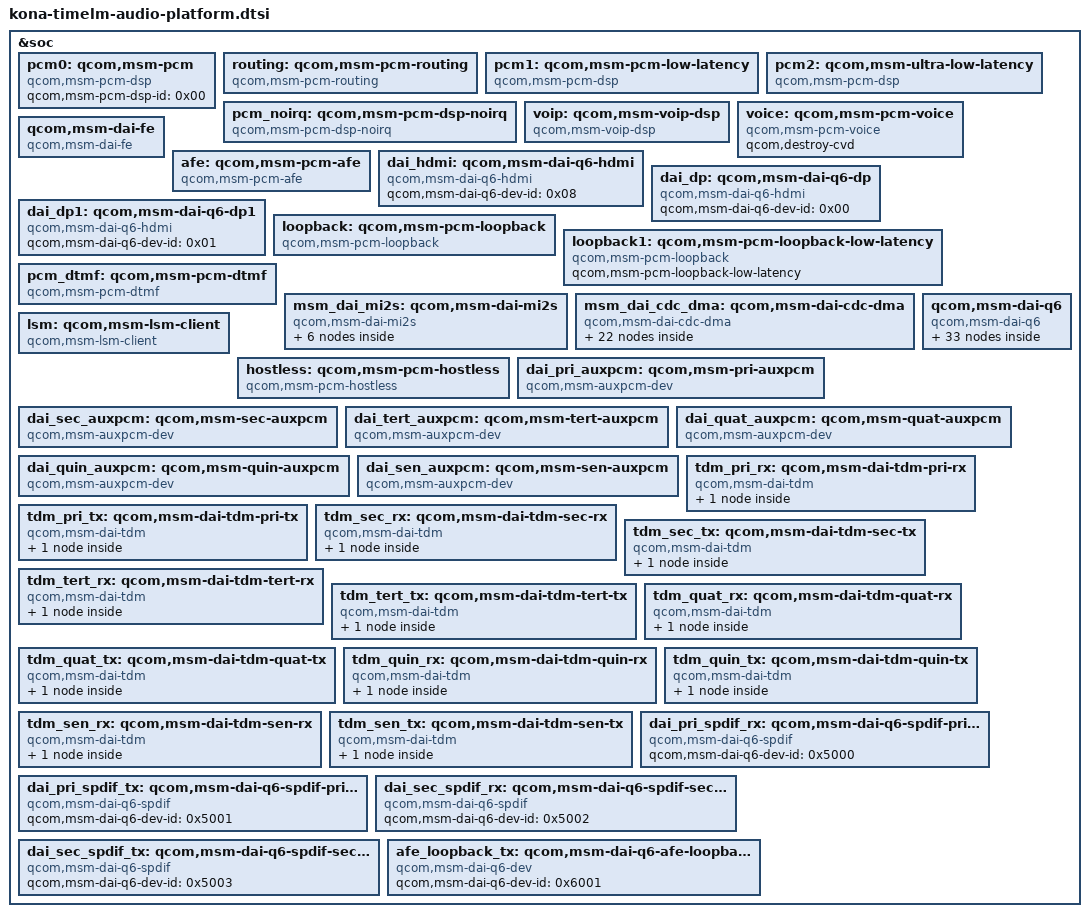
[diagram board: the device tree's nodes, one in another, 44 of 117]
/* Generated by timelm-bsp/tools/extract-live-nodes.py from v60-live.dts */
&soc {
	pcm0: qcom,msm-pcm {
		compatible = "qcom,msm-pcm-dsp";
		qcom,msm-pcm-dsp-id = <0x00>;
	};

	routing: qcom,msm-pcm-routing {
		compatible = "qcom,msm-pcm-routing";
	};

	pcm1: qcom,msm-pcm-low-latency {
		compatible = "qcom,msm-pcm-dsp";
		qcom,msm-pcm-dsp-id = <0x01>;
		qcom,msm-pcm-low-latency;
		qcom,latency-level = "regular";
	};

	pcm2: qcom,msm-ultra-low-latency {
		compatible = "qcom,msm-pcm-dsp";
		qcom,msm-pcm-dsp-id = <0x02>;
		qcom,msm-pcm-low-latency;
		qcom,latency-level = "ultra";
	};

	pcm_noirq: qcom,msm-pcm-dsp-noirq {
		compatible = "qcom,msm-pcm-dsp-noirq";
		qcom,msm-pcm-low-latency;
		qcom,latency-level = "ultra";
	};

	voip: qcom,msm-voip-dsp {
		compatible = "qcom,msm-voip-dsp";
	};

	voice: qcom,msm-pcm-voice {
		compatible = "qcom,msm-pcm-voice";
		qcom,destroy-cvd;
	};

	qcom,msm-dai-fe {
		compatible = "qcom,msm-dai-fe";
	};

	afe: qcom,msm-pcm-afe {
		compatible = "qcom,msm-pcm-afe";
	};

	dai_hdmi: qcom,msm-dai-q6-hdmi {
		compatible = "qcom,msm-dai-q6-hdmi";
		qcom,msm-dai-q6-dev-id = <0x08>;
	};

	dai_dp: qcom,msm-dai-q6-dp {
		compatible = "qcom,msm-dai-q6-hdmi";
		qcom,msm-dai-q6-dev-id = <0x00>;
	};

	dai_dp1: qcom,msm-dai-q6-dp1 {
		compatible = "qcom,msm-dai-q6-hdmi";
		qcom,msm-dai-q6-dev-id = <0x01>;
	};

	loopback: qcom,msm-pcm-loopback {
		compatible = "qcom,msm-pcm-loopback";
	};

	loopback1: qcom,msm-pcm-loopback-low-latency {
		compatible = "qcom,msm-pcm-loopback";
		qcom,msm-pcm-loopback-low-latency;
	};

	pcm_dtmf: qcom,msm-pcm-dtmf {
		compatible = "qcom,msm-pcm-dtmf";
	};

	msm_dai_mi2s: qcom,msm-dai-mi2s {
		compatible = "qcom,msm-dai-mi2s";

		dai_mi2s0: qcom,msm-dai-q6-mi2s-prim {
			compatible = "qcom,msm-dai-q6-mi2s";
			qcom,msm-dai-q6-mi2s-dev-id = <0x00>;
			qcom,msm-mi2s-rx-lines = <0x02>;
			qcom,msm-mi2s-tx-lines = <0x01>;
			pinctrl-names = "default", "sleep";
			pinctrl-0 = <&pri_mi2s_sck_active &pri_mi2s_ws_active &pri_mi2s_sd0_active &pri_mi2s_sd1_active>;
			pinctrl-1 = <&pri_mi2s_sck_sleep &pri_mi2s_ws_sleep &pri_mi2s_sd0_sleep &pri_mi2s_sd1_sleep>;
		};

		dai_mi2s1: qcom,msm-dai-q6-mi2s-sec {
			compatible = "qcom,msm-dai-q6-mi2s";
			qcom,msm-dai-q6-mi2s-dev-id = <0x01>;
			qcom,msm-mi2s-rx-lines = <0x02>;
			qcom,msm-mi2s-tx-lines = <0x01>;
		};

		dai_mi2s2: qcom,msm-dai-q6-mi2s-tert {
			compatible = "qcom,msm-dai-q6-mi2s";
			qcom,msm-dai-q6-mi2s-dev-id = <0x02>;
			qcom,msm-mi2s-rx-lines = <0x02>;
			qcom,msm-mi2s-tx-lines = <0x03>;
			pinctrl-names = "default", "sleep";
			pinctrl-0 = <&tert_mi2s_sck_active &tert_mi2s_ws_active &tert_mi2s_sd1_active>;
			pinctrl-1 = <&tert_mi2s_sck_sleep &tert_mi2s_ws_sleep &tert_mi2s_sd1_sleep>;
		};

		dai_mi2s3: qcom,msm-dai-q6-mi2s-quat {
			compatible = "qcom,msm-dai-q6-mi2s";
			qcom,msm-dai-q6-mi2s-dev-id = <0x03>;
			qcom,msm-mi2s-rx-lines = <0x01>;
			qcom,msm-mi2s-tx-lines = <0x02>;
		};

		dai_mi2s4: qcom,msm-dai-q6-mi2s-quin {
			compatible = "qcom,msm-dai-q6-mi2s";
			qcom,msm-dai-q6-mi2s-dev-id = <0x04>;
			qcom,msm-mi2s-rx-lines = <0x01>;
			qcom,msm-mi2s-tx-lines = <0x02>;
		};

		dai_mi2s5: qcom,msm-dai-q6-mi2s-senary {
			compatible = "qcom,msm-dai-q6-mi2s";
			qcom,msm-dai-q6-mi2s-dev-id = <0x05>;
			qcom,msm-mi2s-rx-lines = <0x00>;
			qcom,msm-mi2s-tx-lines = <0x01>;
		};
	};

	msm_dai_cdc_dma: qcom,msm-dai-cdc-dma {
		compatible = "qcom,msm-dai-cdc-dma";

		wsa_cdc_dma_0_rx: qcom,msm-dai-wsa-cdc-dma-0-rx {
			compatible = "qcom,msm-dai-cdc-dma-dev";
			qcom,msm-dai-cdc-dma-dev-id = <0xb000>;
		};

		wsa_cdc_dma_0_tx: qcom,msm-dai-wsa-cdc-dma-0-tx {
			compatible = "qcom,msm-dai-cdc-dma-dev";
			qcom,msm-dai-cdc-dma-dev-id = <0xb001>;
		};

		wsa_cdc_dma_1_rx: qcom,msm-dai-wsa-cdc-dma-1-rx {
			compatible = "qcom,msm-dai-cdc-dma-dev";
			qcom,msm-dai-cdc-dma-dev-id = <0xb002>;
		};

		wsa_cdc_dma_1_tx: qcom,msm-dai-wsa-cdc-dma-1-tx {
			compatible = "qcom,msm-dai-cdc-dma-dev";
			qcom,msm-dai-cdc-dma-dev-id = <0xb003>;
		};

		wsa_cdc_dma_2_tx: qcom,msm-dai-wsa-cdc-dma-2-tx {
			compatible = "qcom,msm-dai-cdc-dma-dev";
			qcom,msm-dai-cdc-dma-dev-id = <0xb005>;
		};

		va_cdc_dma_0_tx: qcom,msm-dai-va-cdc-dma-0-tx {
			compatible = "qcom,msm-dai-cdc-dma-dev";
			qcom,msm-dai-cdc-dma-dev-id = <0xb021>;
			qcom,msm-dai-is-island-supported = <0x01>;
		};

		va_cdc_dma_1_tx: qcom,msm-dai-va-cdc-dma-1-tx {
			compatible = "qcom,msm-dai-cdc-dma-dev";
			qcom,msm-dai-cdc-dma-dev-id = <0xb023>;
		};

		va_cdc_dma_2_tx: qcom,msm-dai-va-cdc-dma-2-tx {
			compatible = "qcom,msm-dai-cdc-dma-dev";
			qcom,msm-dai-cdc-dma-dev-id = <0xb025>;
		};

		rx_cdc_dma_0_rx: qcom,msm-dai-rx-cdc-dma-0-rx {
			compatible = "qcom,msm-dai-cdc-dma-dev";
			qcom,msm-dai-cdc-dma-dev-id = <0xb030>;
		};

		rx_cdc_dma_1_rx: qcom,msm-dai-rx-cdc-dma-1-rx {
			compatible = "qcom,msm-dai-cdc-dma-dev";
			qcom,msm-dai-cdc-dma-dev-id = <0xb032>;
		};

		rx_cdc_dma_2_rx: qcom,msm-dai-rx-cdc-dma-2-rx {
			compatible = "qcom,msm-dai-cdc-dma-dev";
			qcom,msm-dai-cdc-dma-dev-id = <0xb034>;
		};

		rx_cdc_dma_3_rx: qcom,msm-dai-rx-cdc-dma-3-rx {
			compatible = "qcom,msm-dai-cdc-dma-dev";
			qcom,msm-dai-cdc-dma-dev-id = <0xb036>;
		};

		rx_cdc_dma_4_rx: qcom,msm-dai-rx-cdc-dma-4-rx {
			compatible = "qcom,msm-dai-cdc-dma-dev";
			qcom,msm-dai-cdc-dma-dev-id = <0xb038>;
		};

		rx_cdc_dma_5_rx: qcom,msm-dai-rx-cdc-dma-5-rx {
			compatible = "qcom,msm-dai-cdc-dma-dev";
			qcom,msm-dai-cdc-dma-dev-id = <0xb03a>;
		};

		rx_cdc_dma_6_rx: qcom,msm-dai-rx-cdc-dma-6-rx {
			compatible = "qcom,msm-dai-cdc-dma-dev";
			qcom,msm-dai-cdc-dma-dev-id = <0xb03c>;
		};

		rx_cdc_dma_7_rx: qcom,msm-dai-rx-cdc-dma-7-rx {
			compatible = "qcom,msm-dai-cdc-dma-dev";
			qcom,msm-dai-cdc-dma-dev-id = <0xb03e>;
		};

		tx_cdc_dma_0_tx: qcom,msm-dai-tx-cdc-dma-0-tx {
			compatible = "qcom,msm-dai-cdc-dma-dev";
			qcom,msm-dai-cdc-dma-dev-id = <0xb031>;
		};

		tx_cdc_dma_1_tx: qcom,msm-dai-tx-cdc-dma-1-tx {
			compatible = "qcom,msm-dai-cdc-dma-dev";
			qcom,msm-dai-cdc-dma-dev-id = <0xb033>;
		};

		tx_cdc_dma_2_tx: qcom,msm-dai-tx-cdc-dma-2-tx {
			compatible = "qcom,msm-dai-cdc-dma-dev";
			qcom,msm-dai-cdc-dma-dev-id = <0xb035>;
		};

		tx_cdc_dma_3_tx: qcom,msm-dai-tx-cdc-dma-3-tx {
			compatible = "qcom,msm-dai-cdc-dma-dev";
			qcom,msm-dai-cdc-dma-dev-id = <0xb037>;
		};

		tx_cdc_dma_4_tx: qcom,msm-dai-tx-cdc-dma-4-tx {
			compatible = "qcom,msm-dai-cdc-dma-dev";
			qcom,msm-dai-cdc-dma-dev-id = <0xb039>;
		};

		tx_cdc_dma_5_tx: qcom,msm-dai-tx-cdc-dma-5-tx {
			compatible = "qcom,msm-dai-cdc-dma-dev";
			qcom,msm-dai-cdc-dma-dev-id = <0xb03b>;
		};
	};

	lsm: qcom,msm-lsm-client {
		compatible = "qcom,msm-lsm-client";
	};

	qcom,msm-dai-q6 {
		compatible = "qcom,msm-dai-q6";

		sb_0_rx: qcom,msm-dai-q6-sb-0-rx {
			compatible = "qcom,msm-dai-q6-dev";
			qcom,msm-dai-q6-dev-id = <0x4000>;
		};

		sb_0_tx: qcom,msm-dai-q6-sb-0-tx {
			compatible = "qcom,msm-dai-q6-dev";
			qcom,msm-dai-q6-dev-id = <0x4001>;
		};

		sb_1_rx: qcom,msm-dai-q6-sb-1-rx {
			compatible = "qcom,msm-dai-q6-dev";
			qcom,msm-dai-q6-dev-id = <0x4002>;
		};

		sb_1_tx: qcom,msm-dai-q6-sb-1-tx {
			compatible = "qcom,msm-dai-q6-dev";
			qcom,msm-dai-q6-dev-id = <0x4003>;
		};

		sb_2_rx: qcom,msm-dai-q6-sb-2-rx {
			compatible = "qcom,msm-dai-q6-dev";
			qcom,msm-dai-q6-dev-id = <0x4004>;
		};

		sb_2_tx: qcom,msm-dai-q6-sb-2-tx {
			compatible = "qcom,msm-dai-q6-dev";
			qcom,msm-dai-q6-dev-id = <0x4005>;
		};

		sb_3_rx: qcom,msm-dai-q6-sb-3-rx {
			compatible = "qcom,msm-dai-q6-dev";
			qcom,msm-dai-q6-dev-id = <0x4006>;
		};

		sb_3_tx: qcom,msm-dai-q6-sb-3-tx {
			compatible = "qcom,msm-dai-q6-dev";
			qcom,msm-dai-q6-dev-id = <0x4007>;
		};

		sb_4_rx: qcom,msm-dai-q6-sb-4-rx {
			compatible = "qcom,msm-dai-q6-dev";
			qcom,msm-dai-q6-dev-id = <0x4008>;
		};

		sb_4_tx: qcom,msm-dai-q6-sb-4-tx {
			compatible = "qcom,msm-dai-q6-dev";
			qcom,msm-dai-q6-dev-id = <0x4009>;
		};

		sb_5_tx: qcom,msm-dai-q6-sb-5-tx {
			compatible = "qcom,msm-dai-q6-dev";
			qcom,msm-dai-q6-dev-id = <0x400b>;
		};

		sb_5_rx: qcom,msm-dai-q6-sb-5-rx {
			compatible = "qcom,msm-dai-q6-dev";
			qcom,msm-dai-q6-dev-id = <0x400a>;
		};

		sb_6_rx: qcom,msm-dai-q6-sb-6-rx {
			compatible = "qcom,msm-dai-q6-dev";
			qcom,msm-dai-q6-dev-id = <0x400c>;
		};

		sb_7_rx: qcom,msm-dai-q6-sb-7-rx {
			compatible = "qcom,msm-dai-q6-dev";
			qcom,msm-dai-q6-dev-id = <0x400e>;
			qcom,msm-dai-q6-slim-dev-id = <0x00>;
		};

		sb_7_tx: qcom,msm-dai-q6-sb-7-tx {
			compatible = "qcom,msm-dai-q6-dev";
			qcom,msm-dai-q6-dev-id = <0x400f>;
			qcom,msm-dai-q6-slim-dev-id = <0x00>;
		};

		sb_8_rx: qcom,msm-dai-q6-sb-8-rx {
			compatible = "qcom,msm-dai-q6-dev";
			qcom,msm-dai-q6-dev-id = <0x4010>;
		};

		sb_8_tx: qcom,msm-dai-q6-sb-8-tx {
			compatible = "qcom,msm-dai-q6-dev";
			qcom,msm-dai-q6-dev-id = <0x4011>;
			qcom,msm-dai-q6-slim-dev-id = <0x00>;
		};

		bt_sco_rx: qcom,msm-dai-q6-bt-sco-rx {
			compatible = "qcom,msm-dai-q6-dev";
			qcom,msm-dai-q6-dev-id = <0x3000>;
		};

		bt_sco_tx: qcom,msm-dai-q6-bt-sco-tx {
			compatible = "qcom,msm-dai-q6-dev";
			qcom,msm-dai-q6-dev-id = <0x3001>;
		};

		int_fm_rx: qcom,msm-dai-q6-int-fm-rx {
			compatible = "qcom,msm-dai-q6-dev";
			qcom,msm-dai-q6-dev-id = <0x3004>;
		};

		int_fm_tx: qcom,msm-dai-q6-int-fm-tx {
			compatible = "qcom,msm-dai-q6-dev";
			qcom,msm-dai-q6-dev-id = <0x3005>;
		};

		afe_pcm_rx: qcom,msm-dai-q6-be-afe-pcm-rx {
			compatible = "qcom,msm-dai-q6-dev";
			qcom,msm-dai-q6-dev-id = <0xe0>;
		};

		afe_pcm_tx: qcom,msm-dai-q6-be-afe-pcm-tx {
			compatible = "qcom,msm-dai-q6-dev";
			qcom,msm-dai-q6-dev-id = <0xe1>;
		};

		afe_proxy_rx: qcom,msm-dai-q6-afe-proxy-rx {
			compatible = "qcom,msm-dai-q6-dev";
			qcom,msm-dai-q6-dev-id = <0xf1>;
		};

		afe_proxy_tx: qcom,msm-dai-q6-afe-proxy-tx {
			compatible = "qcom,msm-dai-q6-dev";
			qcom,msm-dai-q6-dev-id = <0xf0>;
		};

		incall_record_rx: qcom,msm-dai-q6-incall-record-rx {
			compatible = "qcom,msm-dai-q6-dev";
			qcom,msm-dai-q6-dev-id = <0x8003>;
		};

		incall_record_tx: qcom,msm-dai-q6-incall-record-tx {
			compatible = "qcom,msm-dai-q6-dev";
			qcom,msm-dai-q6-dev-id = <0x8004>;
		};

		incall_music_rx: qcom,msm-dai-q6-incall-music-rx {
			compatible = "qcom,msm-dai-q6-dev";
			qcom,msm-dai-q6-dev-id = <0x8005>;
		};

		incall_music_2_rx: qcom,msm-dai-q6-incall-music-2-rx {
			compatible = "qcom,msm-dai-q6-dev";
			qcom,msm-dai-q6-dev-id = <0x8002>;
		};

		proxy_rx: qcom,msm-dai-q6-proxy-rx {
			compatible = "qcom,msm-dai-q6-dev";
			qcom,msm-dai-q6-dev-id = <0x2002>;
		};

		proxy_tx: qcom,msm-dai-q6-proxy-tx {
			compatible = "qcom,msm-dai-q6-dev";
			qcom,msm-dai-q6-dev-id = <0x2003>;
		};

		usb_audio_rx: qcom,msm-dai-q6-usb-audio-rx {
			compatible = "qcom,msm-dai-q6-dev";
			qcom,msm-dai-q6-dev-id = <0x7000>;
		};

		usb_audio_tx: qcom,msm-dai-q6-usb-audio-tx {
			compatible = "qcom,msm-dai-q6-dev";
			qcom,msm-dai-q6-dev-id = <0x7001>;
		};
	};

	hostless: qcom,msm-pcm-hostless {
		compatible = "qcom,msm-pcm-hostless";
	};

	dai_pri_auxpcm: qcom,msm-pri-auxpcm {
		compatible = "qcom,msm-auxpcm-dev";
		qcom,msm-cpudai-auxpcm-mode = <0x00 0x00>;
		qcom,msm-cpudai-auxpcm-sync = <0x01 0x01>;
		qcom,msm-cpudai-auxpcm-frame = <0x05 0x04>;
		qcom,msm-cpudai-auxpcm-quant = <0x02 0x02>;
		qcom,msm-cpudai-auxpcm-num-slots = <0x01 0x01>;
		qcom,msm-cpudai-auxpcm-slot-mapping = <0x01 0x01>;
		qcom,msm-cpudai-auxpcm-data = <0x00 0x00>;
		qcom,msm-cpudai-auxpcm-pcm-clk-rate = <0x1f4000 0x1f4000>;
		qcom,msm-auxpcm-interface = "primary";
		qcom,msm-cpudai-afe-clk-ver = <0x02>;
	};

	dai_sec_auxpcm: qcom,msm-sec-auxpcm {
		compatible = "qcom,msm-auxpcm-dev";
		qcom,msm-cpudai-auxpcm-mode = <0x00 0x00>;
		qcom,msm-cpudai-auxpcm-sync = <0x01 0x01>;
		qcom,msm-cpudai-auxpcm-frame = <0x05 0x04>;
		qcom,msm-cpudai-auxpcm-quant = <0x02 0x02>;
		qcom,msm-cpudai-auxpcm-num-slots = <0x01 0x01>;
		qcom,msm-cpudai-auxpcm-slot-mapping = <0x01 0x01>;
		qcom,msm-cpudai-auxpcm-data = <0x00 0x00>;
		qcom,msm-cpudai-auxpcm-pcm-clk-rate = <0x1f4000 0x1f4000>;
		qcom,msm-auxpcm-interface = "secondary";
		qcom,msm-cpudai-afe-clk-ver = <0x02>;
	};

	dai_tert_auxpcm: qcom,msm-tert-auxpcm {
		compatible = "qcom,msm-auxpcm-dev";
		qcom,msm-cpudai-auxpcm-mode = <0x00 0x00>;
		qcom,msm-cpudai-auxpcm-sync = <0x01 0x01>;
		qcom,msm-cpudai-auxpcm-frame = <0x05 0x04>;
		qcom,msm-cpudai-auxpcm-quant = <0x02 0x02>;
		qcom,msm-cpudai-auxpcm-num-slots = <0x01 0x01>;
		qcom,msm-cpudai-auxpcm-slot-mapping = <0x01 0x01>;
		qcom,msm-cpudai-auxpcm-data = <0x00 0x00>;
		qcom,msm-cpudai-auxpcm-pcm-clk-rate = <0x1f4000 0x1f4000>;
		qcom,msm-auxpcm-interface = "tertiary";
		qcom,msm-cpudai-afe-clk-ver = <0x02>;
	};

	dai_quat_auxpcm: qcom,msm-quat-auxpcm {
		compatible = "qcom,msm-auxpcm-dev";
		qcom,msm-cpudai-auxpcm-mode = <0x00 0x00>;
		qcom,msm-cpudai-auxpcm-sync = <0x01 0x01>;
		qcom,msm-cpudai-auxpcm-frame = <0x05 0x04>;
		qcom,msm-cpudai-auxpcm-quant = <0x02 0x02>;
		qcom,msm-cpudai-auxpcm-num-slots = <0x01 0x01>;
		qcom,msm-cpudai-auxpcm-slot-mapping = <0x01 0x01>;
		qcom,msm-cpudai-auxpcm-data = <0x00 0x00>;
		qcom,msm-cpudai-auxpcm-pcm-clk-rate = <0x1f4000 0x1f4000>;
		qcom,msm-auxpcm-interface = "quaternary";
		qcom,msm-cpudai-afe-clk-ver = <0x02>;
	};

	dai_quin_auxpcm: qcom,msm-quin-auxpcm {
		compatible = "qcom,msm-auxpcm-dev";
		qcom,msm-cpudai-auxpcm-mode = <0x00 0x00>;
		qcom,msm-cpudai-auxpcm-sync = <0x01 0x01>;
		qcom,msm-cpudai-auxpcm-frame = <0x05 0x04>;
		qcom,msm-cpudai-auxpcm-quant = <0x02 0x02>;
		qcom,msm-cpudai-auxpcm-num-slots = <0x01 0x01>;
		qcom,msm-cpudai-auxpcm-slot-mapping = <0x01 0x01>;
		qcom,msm-cpudai-auxpcm-data = <0x00 0x00>;
		qcom,msm-cpudai-auxpcm-pcm-clk-rate = <0x1f4000 0x1f4000>;
		qcom,msm-auxpcm-interface = "quinary";
		qcom,msm-cpudai-afe-clk-ver = <0x02>;
	};

	dai_sen_auxpcm: qcom,msm-sen-auxpcm {
		compatible = "qcom,msm-auxpcm-dev";
		qcom,msm-cpudai-auxpcm-mode = <0x00 0x00>;
		qcom,msm-cpudai-auxpcm-sync = <0x01 0x01>;
		qcom,msm-cpudai-auxpcm-frame = <0x05 0x04>;
		qcom,msm-cpudai-auxpcm-quant = <0x02 0x02>;
		qcom,msm-cpudai-auxpcm-num-slots = <0x01 0x01>;
		qcom,msm-cpudai-auxpcm-slot-mapping = <0x01 0x01>;
		qcom,msm-cpudai-auxpcm-data = <0x00 0x00>;
		qcom,msm-cpudai-auxpcm-pcm-clk-rate = <0x1f4000 0x1f4000>;
		qcom,msm-auxpcm-interface = "senary";
		qcom,msm-cpudai-afe-clk-ver = <0x02>;
	};

	tdm_pri_rx: qcom,msm-dai-tdm-pri-rx {
		compatible = "qcom,msm-dai-tdm";
		qcom,msm-cpudai-tdm-group-id = <0x9100>;
		qcom,msm-cpudai-tdm-group-num-ports = <0x01>;
		qcom,msm-cpudai-tdm-group-port-id = <0x9000>;
		qcom,msm-cpudai-tdm-clk-rate = <0x177000>;
		qcom,msm-cpudai-tdm-clk-internal = <0x01>;
		qcom,msm-cpudai-tdm-sync-mode = <0x01>;
		qcom,msm-cpudai-tdm-sync-src = <0x01>;
		qcom,msm-cpudai-tdm-data-out = <0x00>;
		qcom,msm-cpudai-tdm-invert-sync = <0x01>;
		qcom,msm-cpudai-tdm-data-delay = <0x01>;

		dai_pri_tdm_rx_0: qcom,msm-dai-q6-tdm-pri-rx-0 {
			compatible = "qcom,msm-dai-q6-tdm";
			qcom,msm-cpudai-tdm-dev-id = <0x9000>;
			qcom,msm-cpudai-tdm-data-align = <0x00>;
		};
	};

	tdm_pri_tx: qcom,msm-dai-tdm-pri-tx {
		compatible = "qcom,msm-dai-tdm";
		qcom,msm-cpudai-tdm-group-id = <0x9101>;
		qcom,msm-cpudai-tdm-group-num-ports = <0x01>;
		qcom,msm-cpudai-tdm-group-port-id = <0x9001>;
		qcom,msm-cpudai-tdm-clk-rate = <0x177000>;
		qcom,msm-cpudai-tdm-clk-internal = <0x01>;
		qcom,msm-cpudai-tdm-sync-mode = <0x01>;
		qcom,msm-cpudai-tdm-sync-src = <0x01>;
		qcom,msm-cpudai-tdm-data-out = <0x00>;
		qcom,msm-cpudai-tdm-invert-sync = <0x01>;
		qcom,msm-cpudai-tdm-data-delay = <0x01>;

		dai_pri_tdm_tx_0: qcom,msm-dai-q6-tdm-pri-tx-0 {
			compatible = "qcom,msm-dai-q6-tdm";
			qcom,msm-cpudai-tdm-dev-id = <0x9001>;
			qcom,msm-cpudai-tdm-data-align = <0x00>;
		};
	};

	tdm_sec_rx: qcom,msm-dai-tdm-sec-rx {
		compatible = "qcom,msm-dai-tdm";
		qcom,msm-cpudai-tdm-group-id = <0x9110>;
		qcom,msm-cpudai-tdm-group-num-ports = <0x01>;
		qcom,msm-cpudai-tdm-group-port-id = <0x9010>;
		qcom,msm-cpudai-tdm-clk-rate = <0x177000>;
		qcom,msm-cpudai-tdm-clk-internal = <0x01>;
		qcom,msm-cpudai-tdm-sync-mode = <0x01>;
		qcom,msm-cpudai-tdm-sync-src = <0x01>;
		qcom,msm-cpudai-tdm-data-out = <0x00>;
		qcom,msm-cpudai-tdm-invert-sync = <0x01>;
		qcom,msm-cpudai-tdm-data-delay = <0x01>;

		dai_sec_tdm_rx_0: qcom,msm-dai-q6-tdm-sec-rx-0 {
			compatible = "qcom,msm-dai-q6-tdm";
			qcom,msm-cpudai-tdm-dev-id = <0x9010>;
			qcom,msm-cpudai-tdm-data-align = <0x00>;
		};
	};

	tdm_sec_tx: qcom,msm-dai-tdm-sec-tx {
		compatible = "qcom,msm-dai-tdm";
		qcom,msm-cpudai-tdm-group-id = <0x9111>;
		qcom,msm-cpudai-tdm-group-num-ports = <0x01>;
		qcom,msm-cpudai-tdm-group-port-id = <0x9011>;
		qcom,msm-cpudai-tdm-clk-rate = <0x177000>;
		qcom,msm-cpudai-tdm-clk-internal = <0x01>;
		qcom,msm-cpudai-tdm-sync-mode = <0x01>;
		qcom,msm-cpudai-tdm-sync-src = <0x01>;
		qcom,msm-cpudai-tdm-data-out = <0x00>;
		qcom,msm-cpudai-tdm-invert-sync = <0x01>;
		qcom,msm-cpudai-tdm-data-delay = <0x01>;

		dai_sec_tdm_tx_0: qcom,msm-dai-q6-tdm-sec-tx-0 {
			compatible = "qcom,msm-dai-q6-tdm";
			qcom,msm-cpudai-tdm-dev-id = <0x9011>;
			qcom,msm-cpudai-tdm-data-align = <0x00>;
		};
	};

	tdm_tert_rx: qcom,msm-dai-tdm-tert-rx {
		compatible = "qcom,msm-dai-tdm";
		qcom,msm-cpudai-tdm-group-id = <0x9120>;
		qcom,msm-cpudai-tdm-group-num-ports = <0x01>;
		qcom,msm-cpudai-tdm-group-port-id = <0x9020>;
		qcom,msm-cpudai-tdm-clk-rate = <0x177000>;
		qcom,msm-cpudai-tdm-clk-internal = <0x01>;
		qcom,msm-cpudai-tdm-sync-mode = <0x01>;
		qcom,msm-cpudai-tdm-sync-src = <0x01>;
		qcom,msm-cpudai-tdm-data-out = <0x00>;
		qcom,msm-cpudai-tdm-invert-sync = <0x01>;
		qcom,msm-cpudai-tdm-data-delay = <0x01>;

		dai_tert_tdm_rx_0: qcom,msm-dai-q6-tdm-tert-rx-0 {
			compatible = "qcom,msm-dai-q6-tdm";
			qcom,msm-cpudai-tdm-dev-id = <0x9020>;
			qcom,msm-cpudai-tdm-data-align = <0x00>;
		};
	};

	tdm_tert_tx: qcom,msm-dai-tdm-tert-tx {
		compatible = "qcom,msm-dai-tdm";
		qcom,msm-cpudai-tdm-group-id = <0x9121>;
		qcom,msm-cpudai-tdm-group-num-ports = <0x01>;
		qcom,msm-cpudai-tdm-group-port-id = <0x9021>;
		qcom,msm-cpudai-tdm-clk-rate = <0x177000>;
		qcom,msm-cpudai-tdm-clk-internal = <0x01>;
		qcom,msm-cpudai-tdm-sync-mode = <0x01>;
		qcom,msm-cpudai-tdm-sync-src = <0x01>;
		qcom,msm-cpudai-tdm-data-out = <0x00>;
		qcom,msm-cpudai-tdm-invert-sync = <0x01>;
		qcom,msm-cpudai-tdm-data-delay = <0x01>;

		dai_tert_tdm_tx_0: qcom,msm-dai-q6-tdm-tert-tx-0 {
			compatible = "qcom,msm-dai-q6-tdm";
			qcom,msm-cpudai-tdm-dev-id = <0x9021>;
			qcom,msm-cpudai-tdm-data-align = <0x00>;
		};
	};

	tdm_quat_rx: qcom,msm-dai-tdm-quat-rx {
		compatible = "qcom,msm-dai-tdm";
		qcom,msm-cpudai-tdm-group-id = <0x9130>;
		qcom,msm-cpudai-tdm-group-num-ports = <0x01>;
		qcom,msm-cpudai-tdm-group-port-id = <0x9030>;
		qcom,msm-cpudai-tdm-clk-rate = <0x177000>;
		qcom,msm-cpudai-tdm-clk-internal = <0x01>;
		qcom,msm-cpudai-tdm-sync-mode = <0x01>;
		qcom,msm-cpudai-tdm-sync-src = <0x01>;
		qcom,msm-cpudai-tdm-data-out = <0x00>;
		qcom,msm-cpudai-tdm-invert-sync = <0x01>;
		qcom,msm-cpudai-tdm-data-delay = <0x01>;

		dai_quat_tdm_rx_0: qcom,msm-dai-q6-tdm-quat-rx-0 {
			compatible = "qcom,msm-dai-q6-tdm";
			qcom,msm-cpudai-tdm-dev-id = <0x9030>;
			qcom,msm-cpudai-tdm-data-align = <0x00>;
		};
	};

	tdm_quat_tx: qcom,msm-dai-tdm-quat-tx {
		compatible = "qcom,msm-dai-tdm";
		qcom,msm-cpudai-tdm-group-id = <0x9131>;
		qcom,msm-cpudai-tdm-group-num-ports = <0x01>;
		qcom,msm-cpudai-tdm-group-port-id = <0x9031>;
		qcom,msm-cpudai-tdm-clk-rate = <0x177000>;
		qcom,msm-cpudai-tdm-clk-internal = <0x01>;
		qcom,msm-cpudai-tdm-sync-mode = <0x01>;
		qcom,msm-cpudai-tdm-sync-src = <0x01>;
		qcom,msm-cpudai-tdm-data-out = <0x00>;
		qcom,msm-cpudai-tdm-invert-sync = <0x01>;
		qcom,msm-cpudai-tdm-data-delay = <0x01>;

		dai_quat_tdm_tx_0: qcom,msm-dai-q6-tdm-quat-tx-0 {
			compatible = "qcom,msm-dai-q6-tdm";
			qcom,msm-cpudai-tdm-dev-id = <0x9031>;
			qcom,msm-cpudai-tdm-data-align = <0x00>;
		};
	};

	tdm_quin_rx: qcom,msm-dai-tdm-quin-rx {
		compatible = "qcom,msm-dai-tdm";
		qcom,msm-cpudai-tdm-group-id = <0x9140>;
		qcom,msm-cpudai-tdm-group-num-ports = <0x01>;
		qcom,msm-cpudai-tdm-group-port-id = <0x9040>;
		qcom,msm-cpudai-tdm-clk-rate = <0x177000>;
		qcom,msm-cpudai-tdm-clk-internal = <0x01>;
		qcom,msm-cpudai-tdm-sync-mode = <0x01>;
		qcom,msm-cpudai-tdm-sync-src = <0x01>;
		qcom,msm-cpudai-tdm-data-out = <0x00>;
		qcom,msm-cpudai-tdm-invert-sync = <0x01>;
		qcom,msm-cpudai-tdm-data-delay = <0x01>;

		dai_quin_tdm_rx_0: qcom,msm-dai-q6-tdm-quin-rx-0 {
			compatible = "qcom,msm-dai-q6-tdm";
			qcom,msm-cpudai-tdm-dev-id = <0x9040>;
			qcom,msm-cpudai-tdm-data-align = <0x00>;
		};
	};

	tdm_quin_tx: qcom,msm-dai-tdm-quin-tx {
		compatible = "qcom,msm-dai-tdm";
		qcom,msm-cpudai-tdm-group-id = <0x9141>;
		qcom,msm-cpudai-tdm-group-num-ports = <0x01>;
		qcom,msm-cpudai-tdm-group-port-id = <0x9041>;
		qcom,msm-cpudai-tdm-clk-rate = <0x177000>;
		qcom,msm-cpudai-tdm-clk-internal = <0x01>;
		qcom,msm-cpudai-tdm-sync-mode = <0x01>;
		qcom,msm-cpudai-tdm-sync-src = <0x01>;
		qcom,msm-cpudai-tdm-data-out = <0x00>;
		qcom,msm-cpudai-tdm-invert-sync = <0x01>;
		qcom,msm-cpudai-tdm-data-delay = <0x01>;

		dai_quin_tdm_tx_0: qcom,msm-dai-q6-tdm-quin-tx-0 {
			compatible = "qcom,msm-dai-q6-tdm";
			qcom,msm-cpudai-tdm-dev-id = <0x9041>;
			qcom,msm-cpudai-tdm-data-align = <0x00>;
		};
	};

	tdm_sen_rx: qcom,msm-dai-tdm-sen-rx {
		compatible = "qcom,msm-dai-tdm";
		qcom,msm-cpudai-tdm-group-id = <0x9150>;
		qcom,msm-cpudai-tdm-group-num-ports = <0x01>;
		qcom,msm-cpudai-tdm-group-port-id = <0x9050>;
		qcom,msm-cpudai-tdm-clk-rate = <0x177000>;
		qcom,msm-cpudai-tdm-clk-internal = <0x01>;
		qcom,msm-cpudai-tdm-sync-mode = <0x01>;
		qcom,msm-cpudai-tdm-sync-src = <0x01>;
		qcom,msm-cpudai-tdm-data-out = <0x00>;
		qcom,msm-cpudai-tdm-invert-sync = <0x01>;
		qcom,msm-cpudai-tdm-data-delay = <0x01>;

		dai_sen_tdm_rx_0: qcom,msm-dai-q6-tdm-sen-rx-0 {
			compatible = "qcom,msm-dai-q6-tdm";
			qcom,msm-cpudai-tdm-dev-id = <0x9050>;
			qcom,msm-cpudai-tdm-data-align = <0x00>;
		};
	};

	tdm_sen_tx: qcom,msm-dai-tdm-sen-tx {
		compatible = "qcom,msm-dai-tdm";
		qcom,msm-cpudai-tdm-group-id = <0x9151>;
		qcom,msm-cpudai-tdm-group-num-ports = <0x01>;
		qcom,msm-cpudai-tdm-group-port-id = <0x9051>;
		qcom,msm-cpudai-tdm-clk-rate = <0x177000>;
		qcom,msm-cpudai-tdm-clk-internal = <0x01>;
		qcom,msm-cpudai-tdm-sync-mode = <0x01>;
		qcom,msm-cpudai-tdm-sync-src = <0x01>;
		qcom,msm-cpudai-tdm-data-out = <0x00>;
		qcom,msm-cpudai-tdm-invert-sync = <0x01>;
		qcom,msm-cpudai-tdm-data-delay = <0x01>;

		dai_sen_tdm_tx_0: qcom,msm-dai-q6-tdm-sen-tx-0 {
			compatible = "qcom,msm-dai-q6-tdm";
			qcom,msm-cpudai-tdm-dev-id = <0x9051>;
			qcom,msm-cpudai-tdm-data-align = <0x00>;
		};
	};

	dai_pri_spdif_rx: qcom,msm-dai-q6-spdif-pri-rx {
		compatible = "qcom,msm-dai-q6-spdif";
		qcom,msm-dai-q6-dev-id = <0x5000>;
	};

	dai_pri_spdif_tx: qcom,msm-dai-q6-spdif-pri-tx {
		compatible = "qcom,msm-dai-q6-spdif";
		qcom,msm-dai-q6-dev-id = <0x5001>;
	};

	dai_sec_spdif_rx: qcom,msm-dai-q6-spdif-sec-rx {
		compatible = "qcom,msm-dai-q6-spdif";
		qcom,msm-dai-q6-dev-id = <0x5002>;
	};

	dai_sec_spdif_tx: qcom,msm-dai-q6-spdif-sec-tx {
		compatible = "qcom,msm-dai-q6-spdif";
		qcom,msm-dai-q6-dev-id = <0x5003>;
	};

	afe_loopback_tx: qcom,msm-dai-q6-afe-loopback-tx {
		compatible = "qcom,msm-dai-q6-dev";
		qcom,msm-dai-q6-dev-id = <0x6001>;
	};

};
